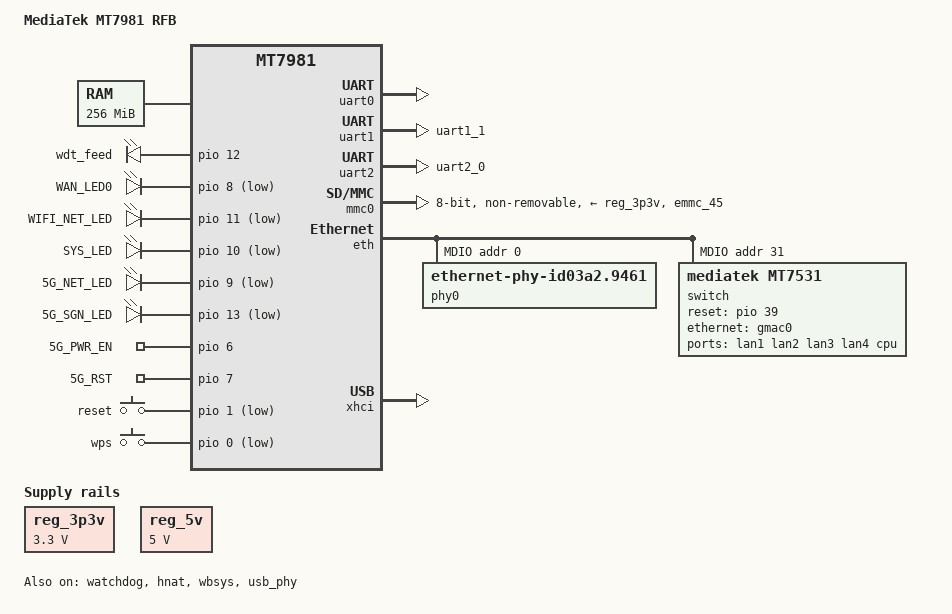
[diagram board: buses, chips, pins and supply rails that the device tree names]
/dts-v1/;
#include "mt7981.dtsi"
#include <dt-bindings/gpio/gpio.h>
#include <dt-bindings/input/input.h>
#include <dt-bindings/leds/common.h>

/ {
	model = "MediaTek MT7981 RFB";
	compatible = "mediatek,mt7981-emmc-r180";
	chosen {
		bootargs = "console=ttyS0,115200n1 loglevel=8  \
				earlycon=uart8250,mmio32,0x11002000 \
				root=PARTLABEL=rootfs rootwait rootfstype=squashfs,f2fs";
	};

	memory {
		// fpga ddr2: 128MB*2
		reg = <0 0x40000000 0 0x10000000>;
	};

	gpio-leds {		
		compatible = "gpio-leds";

		WDT_FEED {
			label = "wdt_feed";
			gpios = <&pio 12 0>;
			default-state = "on";
			linux,default-trigger = "timer";
		};

		WAN_LED0 {
			gpios = <&pio 8 GPIO_ACTIVE_LOW>;
			label = "WAN_LED0";
			default-state = "off";
		};

		WIFI_NET_LED {
			gpios = <&pio 11 GPIO_ACTIVE_LOW>;
			label = "WIFI_NET_LED";
			default-state = "off";
		};

        SYS_LED {
			gpios = <&pio 10 GPIO_ACTIVE_LOW>;
			label = "SYS_LED";
			default-state = "off";
		};

		5G_NET_LED {
			gpios = <&pio 9 GPIO_ACTIVE_LOW>;
			label = "5G_NET_LED";
			default-state = "off";
		};

		5G_SGN_LED {
			gpios = <&pio 13 GPIO_ACTIVE_LOW>;
			label = "5G_SGN_LED";
			default-state = "off";
		};

		5G_PWR_EN {
			gpios = <&pio 6 GPIO_ACTIVE_HIGH>;
			label = "5G_PWR_EN";
			default-state = "on";
		};

		5G_RST {
			gpios = <&pio 7 GPIO_ACTIVE_HIGH>;
			label = "5G_RST";
			default-state = "off";
		};
	};

	gpio-keys {
		compatible = "gpio-keys";

		reset {
			label = "reset";
			linux,code = <KEY_RESTART>;
			gpios = <&pio 1 GPIO_ACTIVE_LOW>;
			debounce-interval = <10>;
		};

		wps {
			label = "wps";
			linux,code = <KEY_WPS_BUTTON>;
			gpios = <&pio 0 GPIO_ACTIVE_LOW>;
			debounce-interval = <10>;
		};
	};

	reg_3p3v: regulator-3p3v {
		compatible = "regulator-fixed";
		regulator-name = "fixed-3.3V";
		regulator-min-microvolt = <3300000>;
		regulator-max-microvolt = <3300000>;
		regulator-boot-on;
		regulator-always-on;
	};

    reg_5v: regulator-5v {
		compatible = "regulator-fixed";
		regulator-name = "fixed-5V";
		regulator-min-microvolt = <5000000>;
		regulator-max-microvolt = <5000000>;
		regulator-boot-on;
		regulator-always-on;
	};
};

&uart0 {
	status = "okay";
};

&uart1 {
	pinctrl-names = "default";
	pinctrl-0 = <&uart1_pins>;
	status = "okay";
};

&uart2 {
	pinctrl-names = "default";
	pinctrl-0 = <&uart2_pins>;
	status = "okay";
};

&watchdog {
	status = "okay";
};

&i2c0 {
	status = "disabled";
	pinctrl-names = "default";
	pinctrl-0 = <&i2c_pins>;
	gpio21: gpio@21 {
		compatible = "nxp,pca9555";
		reg = <0x21>;
		pinctrl-names = "default";
		gpio-controller;
		#gpio-cells = <0x02>;
	};
};

&mmc0 {
         pinctrl-names = "default", "state_uhs";
         pinctrl-0 = <&mmc0_pins_default>;
         pinctrl-1 = <&mmc0_pins_uhs>;
         bus-width = <8>;
         max-frequency = <52000000>;
         cap-mmc-highspeed;
         vmmc-supply = <&reg_3p3v>;
         non-removable;
         status = "okay";
};

&eth {
	status = "okay";

	gmac0: mac@0 {
		compatible = "mediatek,eth-mac";
		reg = <0>;
		phy-mode = "2500base-x";

		fixed-link {
			speed = <2500>;
			full-duplex;
			pause;
		};
	};

	gmac1: mac@1 {
		compatible = "mediatek,eth-mac";
		reg = <1>;
		phy-mode = "gmii";
		phy-handle = <&phy0>;
	};

	mdio: mdio-bus {
		#address-cells = <1>;
		#size-cells = <0>;

		phy0: ethernet-phy@0 {
			compatible = "ethernet-phy-id03a2.9461";
			reg = <0>;
			phy-mode = "gmii";
			nvmem-cells = <&phy_calibration>;
			nvmem-cell-names = "phy-cal-data";
		};

		switch@31 {
			compatible = "mediatek,mt7531";
			reg = <31>;
			reset-gpios = <&pio 39 0>;

			ports {
				#address-cells = <1>;
				#size-cells = <0>;

				port@0 {
					reg = <0>;
					label = "lan1";
				};

                port@1 {
					reg = <1>;
					label = "lan2";
				};
                
                port@2 {
					reg = <2>;
					label = "lan3";
				};
                
                port@3 {
					reg = <3>;
					label = "lan4";
				};

				port@6 {
					reg = <6>;
					label = "cpu";
					ethernet = <&gmac0>;
					phy-mode = "2500base-x";

					fixed-link {
						speed = <2500>;
						full-duplex;
						pause;
					};
				};
			};
		};
	};
};

&hnat {
	mtketh-wan = "eth1";
	mtketh-lan = "lan";
	mtketh-max-gmac = <2>;
	status = "okay";
};

&spi1 {
	pinctrl-names = "default";
	pinctrl-0 = <&spic_pins>;
	status = "disabled";
};

&wbsys {
	status = "okay";
	pinctrl-names = "dbdc";
	pinctrl-0 = <&wf_dbdc_pins>;
};

&pio {
	i2c_pins: i2c-pins-g1 {
        mux {
            function = "i2c";
            groups = "i2c0_0";
        };
    };

	uart1_pins: uart1-pins-g1 {
        mux {
            function = "uart";
            groups = "uart1_1";
        };
    };

	uart2_pins: uart2-pins-g1 {
		mux {
            function = "uart";
            groups = "uart2_0";
        };
    };

	spic_pins: spi1-pins {
		mux {
			function = "spi";
			groups = "spi1_1";
		};
	};

	mmc0_pins_default: mmc0-pins-default {
		mux {
			function = "flash";
			groups = "emmc_45";
		};
	};

	mmc0_pins_uhs: mmc0-pins-uhs {
		mux {
			function = "flash";
			groups = "emmc_45";
		};
	};

	wf_dbdc_pins: wf_dbdc-pins {
		mux {
			function = "eth";
			groups = "wf0_mode1";
		};
		conf {
			pins = "WF_HB1", "WF_HB2", "WF_HB3", "WF_HB4",
			       "WF_HB0", "WF_HB0_B", "WF_HB5", "WF_HB6",
			       "WF_HB7", "WF_HB8", "WF_HB9", "WF_HB10",
			       "WF_TOP_CLK", "WF_TOP_DATA", "WF_XO_REQ",
			       "WF_CBA_RESETB", "WF_DIG_RESETB";
			drive-strength = <MTK_DRIVE_4mA>;
		};
	};
};

&usb_phy {
	status = "okay";
};

&xhci {
	status = "okay";
};
